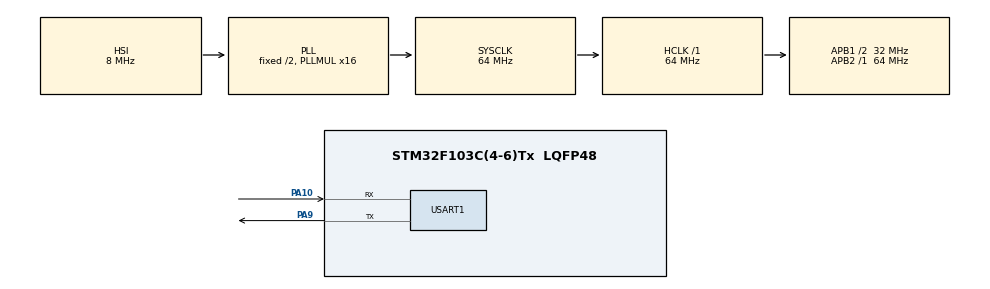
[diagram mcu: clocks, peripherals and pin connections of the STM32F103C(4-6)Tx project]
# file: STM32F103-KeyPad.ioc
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Mcu.Family=STM32F1
Dma.USART1_TX.0.MemInc=DMA_MINC_ENABLE
Dma.USART1_TX.0.PeriphInc=DMA_PINC_DISABLE
PA10.Mode=Asynchronous
RCC.APB1CLKDivider=RCC_HCLK_DIV2
VP_SYS_VS_ND.Mode=No_Debug
RCC.SYSCLKSource=RCC_SYSCLKSOURCE_PLLCLK
ProjectManager.StackSize=0x400
PA9.Mode=Asynchronous
Dma.USART1_TX.0.Priority=DMA_PRIORITY_LOW
Dma.USART1_TX.0.Direction=DMA_MEMORY_TO_PERIPH
ProjectManager.TargetToolchain=MDK-ARM V5.27
RCC.HCLKFreq_Value=64000000
RCC.APB2TimFreq_Value=64000000
PA9.Signal=USART1_TX
RCC.USBFreq_Value=64000000
RCC.AHBFreq_Value=64000000
Dma.USART1_TX.0.Mode=DMA_NORMAL
board=custom
RCC.PLLMUL=RCC_PLL_MUL16
RCC.APB2Freq_Value=64000000
VP_TIM2_VS_ClockSourceINT.Mode=Internal
NVIC.TIM2_IRQn=true\:0\:0\:false\:false\:true\:true\:true
TIM2.Period=49
Dma.USART1_TX.0.PeriphDataAlignment=DMA_PDATAALIGN_BYTE
Mcu.Name=STM32F103C(4-6)Tx
RCC.SYSCLKFreq_VALUE=64000000
Mcu.Package=LQFP48
TIM2.Prescaler=63999
USART1.VirtualMode=VM_ASYNC
Dma.USART1_TX.0.MemDataAlignment=DMA_MDATAALIGN_BYTE
PA10.Signal=USART1_RX
ProjectManager.HeapSize=0x200
Dma.USART1_TX.0.Instance=DMA1_Channel4
NVIC.PriorityGroup=NVIC_PRIORITYGROUP_4
RCC.APB1TimFreq_Value=64000000
NVIC.DMA1_Channel4_IRQn=true\:0\:0\:false\:false\:true\:false\:true
NVIC.USART1_IRQn=true\:0\:0\:false\:false\:true\:true\:true
Dma.Request0=USART1_TX
RCC.APB1Freq_Value=32000000

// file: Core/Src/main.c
/* USER CODE BEGIN Header */
/**
  ******************************************************************************
  * @file           : main.c
  * @brief          : Main program body
  ******************************************************************************
  * @attention
  *
  * <h2><center>&copy; Copyright (c) 2022 STMicroelectronics.
  * All rights reserved.</center></h2>
  *
  * This software component is licensed by ST under BSD 3-Clause license,
  * the "License"; You may not use this file except in compliance with the
  * License. You may obtain a copy of the License at:
  *                        opensource.org/licenses/BSD-3-Clause
  *
  ******************************************************************************
  */
/* USER CODE END Header */
#include "main.h"
#include "dma.h"
#include "tim.h"
#include "usart.h"
#include "gpio.h"

/* USER CODE BEGIN Includes */
#include "KeyPad.h"
#include "KeyPad_Port.h"
#include <stdio.h>
/* USER CODE END Includes */

/* USER CODE BEGIN PV */
static const KeyPad_KeyValue KEYPAD_MAP[] = {
  '7', '8', '9', '/',
  '4', '5', '6', '*',
  '1', '2', '3', '-',
  //'O', '0', '=', '+',
};
static const KeyPad_PinConfig KEYPAD_COLS[] = {
  {KEYPAD_COL_0_GPIO, KEYPAD_COL_0_PIN},
  {KEYPAD_COL_1_GPIO, KEYPAD_COL_1_PIN},
  {KEYPAD_COL_2_GPIO, KEYPAD_COL_2_PIN},
  {KEYPAD_COL_3_GPIO, KEYPAD_COL_3_PIN},
};
static const KeyPad_PinConfig KEYPAD_ROWS[] = {
  {KEYPAD_ROW_0_GPIO, KEYPAD_ROW_0_PIN},
  {KEYPAD_ROW_1_GPIO, KEYPAD_ROW_1_PIN},
  {KEYPAD_ROW_2_GPIO, KEYPAD_ROW_2_PIN},
  //{KEYPAD_ROW_3_GPIO, KEYPAD_ROW_3_PIN},
};

static const KeyPad_Config KEYPAD_CONFIG = KEYPAD_CONFIG_INIT(KEYPAD_MAP, KEYPAD_COLS, KEYPAD_ROWS);

static KeyPad keypad;

/* USER CODE END PV */

void SystemClock_Config(void);
/* USER CODE BEGIN PFP */
KeyPad_HandleStatus onPressed(KeyPad* keypad, KeyPad_KeyValue value, KeyPad_State state);
KeyPad_HandleStatus onHold(KeyPad* keypad, KeyPad_KeyValue value, KeyPad_State state);
KeyPad_HandleStatus onReleased(KeyPad* keypad, KeyPad_KeyValue value, KeyPad_State state);
/* USER CODE END PFP */

int main(void)
{

  /* MCU Configuration--------------------------------------------------------*/

  /* Reset of all peripherals, Initializes the Flash interface and the Systick. */
  HAL_Init();

  /* Configure the system clock */
  SystemClock_Config();

  /* Initialize all configured peripherals */
  MX_GPIO_Init();
  MX_DMA_Init();
  MX_USART1_UART_Init();
  MX_TIM2_Init();
  /* USER CODE BEGIN 2 */
  KeyPad_init(&KEYPAD_DRIVER);

  KeyPad_add(&keypad, &KEYPAD_CONFIG);
  KeyPad_onPressed(&keypad, onPressed);
  KeyPad_onHold(&keypad, onHold);
  KeyPad_onReleased(&keypad, onReleased);

  /* USER CODE END 2 */

  /* Infinite loop */
  /* USER CODE BEGIN WHILE */
  HAL_TIM_Base_Start_IT(&htim2);

  HAL_UART_Transmit(&huart1, (uint8_t*) "Running...\r\n", 12, 1000);

  while (1)
  {
    /* USER CODE END WHILE */

  }
}

void SystemClock_Config(void)
{
  RCC_OscInitTypeDef RCC_OscInitStruct = {0};
  RCC_ClkInitTypeDef RCC_ClkInitStruct = {0};

  /** Initializes the RCC Oscillators according to the specified parameters
  * in the RCC_OscInitTypeDef structure.
  */
  RCC_OscInitStruct.OscillatorType = RCC_OSCILLATORTYPE_HSI;
  RCC_OscInitStruct.HSIState = RCC_HSI_ON;
  RCC_OscInitStruct.HSICalibrationValue = RCC_HSICALIBRATION_DEFAULT;
  RCC_OscInitStruct.PLL.PLLState = RCC_PLL_ON;
  RCC_OscInitStruct.PLL.PLLSource = RCC_PLLSOURCE_HSI_DIV2;
  RCC_OscInitStruct.PLL.PLLMUL = RCC_PLL_MUL16;
  if (HAL_RCC_OscConfig(&RCC_OscInitStruct) != HAL_OK)
  {
    Error_Handler();
  }
  /** Initializes the CPU, AHB and APB buses clocks
  */
  RCC_ClkInitStruct.ClockType = RCC_CLOCKTYPE_HCLK|RCC_CLOCKTYPE_SYSCLK
                              |RCC_CLOCKTYPE_PCLK1|RCC_CLOCKTYPE_PCLK2;
  RCC_ClkInitStruct.SYSCLKSource = RCC_SYSCLKSOURCE_PLLCLK;
  RCC_ClkInitStruct.AHBCLKDivider = RCC_SYSCLK_DIV1;
  RCC_ClkInitStruct.APB1CLKDivider = RCC_HCLK_DIV2;
  RCC_ClkInitStruct.APB2CLKDivider = RCC_HCLK_DIV1;

  if (HAL_RCC_ClockConfig(&RCC_ClkInitStruct, FLASH_LATENCY_2) != HAL_OK)
  {
    Error_Handler();
  }
}

/* USER CODE BEGIN 4 */
KeyPad_HandleStatus onPressed(KeyPad* keypad, KeyPad_KeyValue value, KeyPad_State state) {
  static char str[32];
  if (huart1.gState == HAL_UART_STATE_READY) {
    int len = snprintf(str, sizeof(str), "%c (%u, %u)", value, keypad->RowIndex, keypad->ColIndex);
    HAL_UART_Transmit_DMA(&huart1, (uint8_t*) str, len);
  }
  return KeyPad_NotHandled;
}
KeyPad_HandleStatus onHold(KeyPad* keypad, KeyPad_KeyValue value, KeyPad_State state) {
  static uint32_t nextTick = 0;
  if (nextTick <= HAL_GetTick()) {
    nextTick = HAL_GetTick() + 100;
    HAL_UART_Transmit(&huart1, (uint8_t*) "-", 1, 1);
  }
  return KeyPad_NotHandled;
}
KeyPad_HandleStatus onReleased(KeyPad* keypad, KeyPad_KeyValue value, KeyPad_State state) {
  HAL_UART_Transmit(&huart1, (uint8_t*) "|\r\n", 2, 10);
  return KeyPad_NotHandled;
}

void HAL_TIM_PeriodElapsedCallback(TIM_HandleTypeDef* htim) {
  switch ((uint32_t) htim->Instance) {
    case TIM2_BASE:
      KeyPad_handle();
      break;
  }
}

/* USER CODE END 4 */

void Error_Handler(void)
{
  __disable_irq();
  while (1)
  {
  }
}

/************************ (C) COPYRIGHT STMicroelectronics *****END OF FILE****/
